VERSION ""

NS_ :

BS_:

BU_: VCU AUTO RMT
BO_ 1524 BcmMessage4: 8 VCU
 SG_ Ltemp : 8|8@1+ (1,-40) [-40|215] "℃"    AUTO,   RMT
 SG_ Ntemp : 16|8@1+ (1,-40) [-40|215] "℃"    AUTO,   RMT
 SG_ SafeBeltSta1 : 24|1@1+ (1,0) [0|1] ""    AUTO,   RMT
 SG_ SafeBeltSta2 : 25|1@1+ (1,0) [0|1] ""    AUTO,   RMT
 SG_ SafeBeltSta3 : 26|1@1+ (1,0) [0|1] ""    AUTO,   RMT
 SG_ SafeBeltSta4 : 27|1@1+ (1,0) [0|1] ""    AUTO,   RMT
 SG_ SafeBeltSta5 : 28|1@1+ (1,0) [0|1] ""    AUTO,   RMT
 SG_ SafeBeltSta6 : 29|1@1+ (1,0) [0|1] ""    AUTO,   RMT
 SG_ SeatSta1 : 30|1@1+ (1,0) [0|1] ""    AUTO,   RMT
 SG_ SeatSta2 : 31|1@1+ (1,0) [0|1] ""    AUTO,   RMT
 SG_ SeatSta3 : 32|1@1+ (1,0) [0|1] ""    AUTO,   RMT
 SG_ SeatSta4 : 33|1@1+ (1,0) [0|1] ""    AUTO,   RMT
 SG_ SeatSta5 : 34|1@1+ (1,0) [0|1] ""    AUTO,   RMT
 SG_ SeatSta6 : 35|1@1+ (1,0) [0|1] ""    AUTO,   RMT
 SG_ IoIn13 : 36|1@1+ (1,0) [0|1] ""    AUTO,   RMT
 SG_ IoIn14 : 37|1@1+ (1,0) [0|1] ""    AUTO,   RMT
 SG_ IoIn15 : 38|1@1+ (1,0) [0|1] ""    AUTO,   RMT
 SG_ IoIn16 : 39|1@1+ (1,0) [0|1] ""    AUTO,   RMT
 SG_ IoCur1 : 40|1@1+ (1,0) [0|1] ""    AUTO,   RMT
 SG_ IoCur2 : 41|1@1+ (1,0) [0|1] ""    AUTO,   RMT
 SG_ IoCur3 : 42|1@1+ (1,0) [0|1] ""    AUTO,   RMT
 SG_ IoCur4 : 43|1@1+ (1,0) [0|1] ""    AUTO,   RMT
 SG_ AdCVin : 44|1@1+ (1,0) [0|20] "mV"    AUTO,   RMT
 SG_ AdVVin5 : 46|10@1+ (10,0) [0|10000] "mV"    AUTO,   RMT

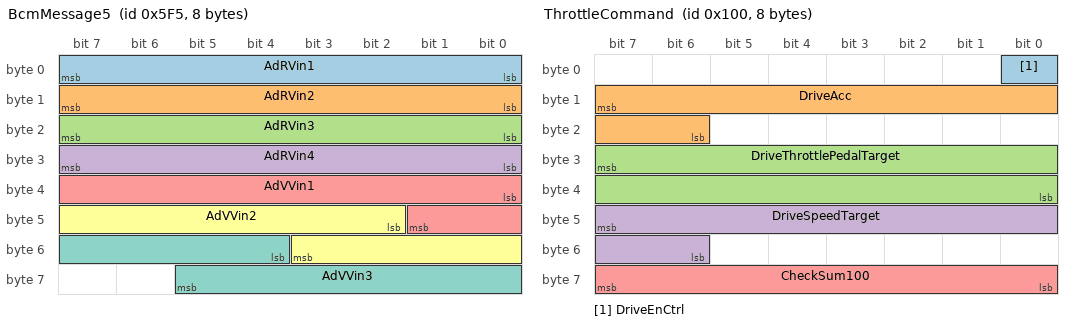
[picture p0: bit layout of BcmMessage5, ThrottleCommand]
BO_ 1525 BcmMessage5: 8 VCU
 SG_ AdRVin1 : 0|8@1+ (2,0) [0|500] "Ω"    AUTO,   RMT
 SG_ AdRVin2 : 8|8@1+ (2,0) [0|500] "Ω"    AUTO,   RMT
 SG_ AdRVin3 : 16|8@1+ (2,0) [0|500] "Ω"    AUTO,   RMT
 SG_ AdRVin4 : 24|8@1+ (2,0) [0|500] "Ω"    AUTO,   RMT
 SG_ AdVVin1 : 32|10@1+ (5,0) [0|3500] "mV"    AUTO,   RMT
 SG_ AdVVin2 : 42|10@1+ (5,0) [0|3500] "mV"    AUTO,   RMT
 SG_ AdVVin3 : 52|10@1+ (5,0) [0|3500] "mV"    AUTO,   RMT

BO_ 256 ThrottleCommand: 8 AUTO
 SG_ DriveEnCtrl : 0|1@0+ (1,0) [0|1] ""   VCU
 SG_ DriveAcc : 15|10@0+ (0.01,0) [0|10] "m/s^2"   VCU
 SG_ DriveThrottlePedalTarget : 31|16@0+ (0.1,0) [0|100] "%"   VCU
 SG_ DriveSpeedTarget : 47|10@0+ (0.01,0) [0|40.95] " m/s"   VCU
 SG_ CheckSum100 : 63|8@0+ (1,0) [0|255] ""   VCU

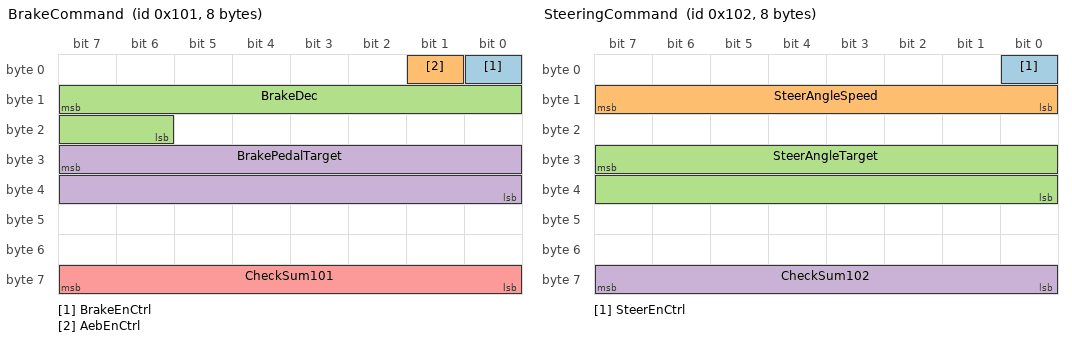
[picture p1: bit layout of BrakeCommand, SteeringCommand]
BO_ 257 BrakeCommand: 8 AUTO
 SG_ BrakeEnCtrl : 0|1@0+ (1,0) [0|1] ""   VCU
 SG_ AebEnCtrl : 1|1@0+ (1,0) [0|1] ""   VCU
 SG_ BrakeDec : 15|10@0+ (0.01,0) [0|10] "m/s^2"   VCU
 SG_ BrakePedalTarget : 31|16@0+ (0.1,0) [0|100] "%"   VCU
 SG_ CheckSum101 : 63|8@0+ (1,0) [0|255] ""   VCU

BO_ 258 SteeringCommand: 8 AUTO
 SG_ SteerEnCtrl : 0|1@0+ (1,0) [0|1] ""   VCU
 SG_ SteerAngleSpeed : 15|8@0+ (1,0) [0|250] "deg/s"   VCU
 SG_ SteerAngleTarget : 31|16@0+ (1,-500) [-465|465] "deg"   VCU
 SG_ CheckSum102 : 63|8@0+ (1,0) [0|255] ""   VCU

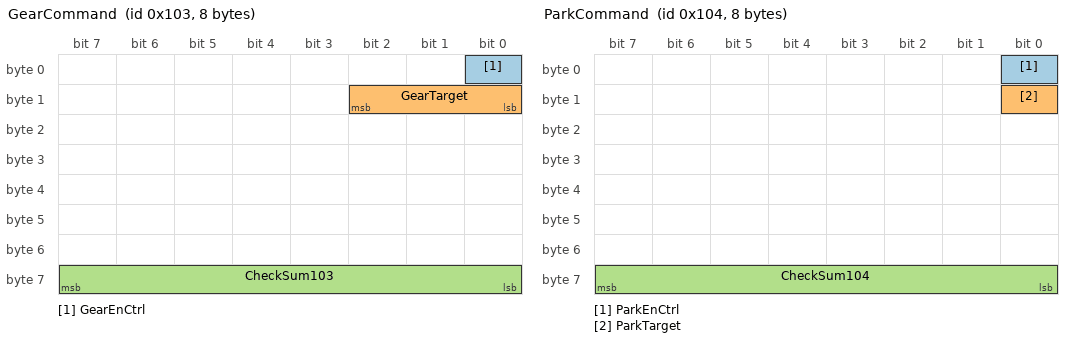
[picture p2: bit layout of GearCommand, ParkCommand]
BO_ 259 GearCommand: 8 AUTO
 SG_ GearEnCtrl : 0|1@0+ (1,0) [0|1] ""   VCU
 SG_ GearTarget : 10|3@0+ (1,0) [0|7] ""   VCU
 SG_ CheckSum103 : 63|8@0+ (1,0) [0|255] ""   VCU

BO_ 260 ParkCommand: 8 AUTO
 SG_ ParkEnCtrl : 0|1@0+ (1,0) [0|1] ""   VCU
 SG_ ParkTarget : 8|1@0+ (1,0) [0|1] ""   VCU
 SG_ CheckSum104 : 63|8@0+ (1,0) [0|255] ""   VCU

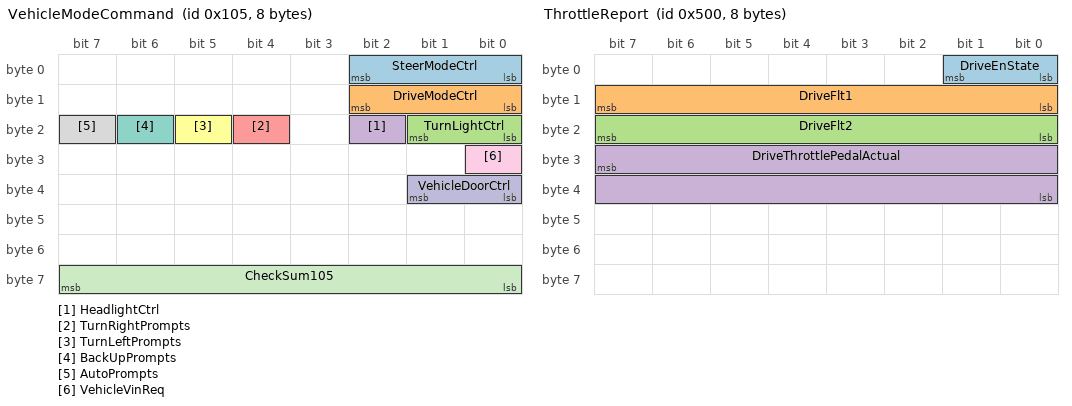
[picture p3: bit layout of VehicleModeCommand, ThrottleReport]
BO_ 261 VehicleModeCommand: 8 AUTO
 SG_ SteerModeCtrl : 2|3@0+ (1,0) [0|7] ""   VCU
 SG_ DriveModeCtrl : 10|3@0+ (1,0) [0|7] ""   VCU
 SG_ TurnLightCtrl : 17|2@0+ (1,0) [0|3] ""   VCU
 SG_ HeadlightCtrl : 18|1@0+ (1,0) [0|1] ""   VCU
 SG_ TurnRightPrompts : 20|1@0+ (1,0) [0|1] ""   VCU
 SG_ TurnLeftPrompts : 21|1@0+ (1,0) [0|1] ""   VCU
 SG_ BackUpPrompts : 22|1@0+ (1,0) [0|1] ""   VCU
 SG_ AutoPrompts : 23|1@0+ (1,0) [0|1] ""   VCU
 SG_ VehicleVinReq : 24|1@0+ (1,0) [0|1] ""   VCU
 SG_ VehicleDoorCtrl : 33|2@0+ (1,0) [0|3] ""   VCU
 SG_ CheckSum105 : 63|8@0+ (1,0) [0|255] ""   VCU

BO_ 1280 ThrottleReport: 8 VCU
 SG_ DriveEnState : 1|2@0+ (1,0) [0|3] ""    AUTO,   RMT
 SG_ DriveFlt1 : 15|8@0+ (1,0) [0|255] ""    AUTO,   RMT
 SG_ DriveFlt2 : 23|8@0+ (1,0) [0|255] ""    AUTO,   RMT
 SG_ DriveThrottlePedalActual : 31|16@0+ (0.1,0) [0|100] "%"    AUTO,   RMT

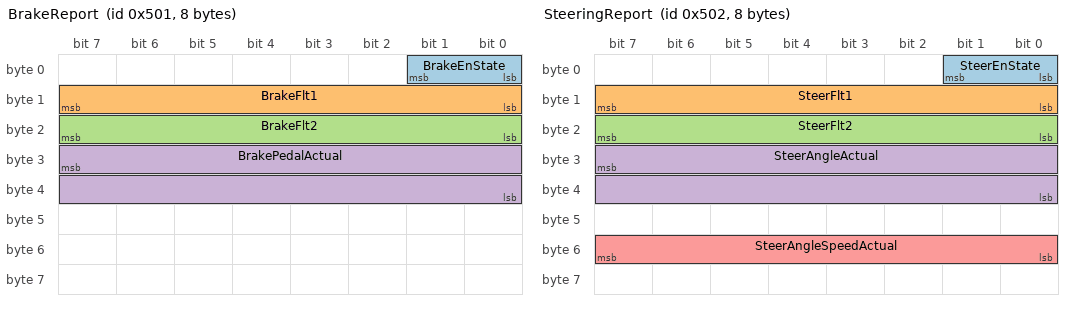
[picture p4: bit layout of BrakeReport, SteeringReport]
BO_ 1281 BrakeReport: 8 VCU
 SG_ BrakeEnState : 1|2@0+ (1,0) [0|3] ""    AUTO,   RMT
 SG_ BrakeFlt1 : 15|8@0+ (1,0) [0|255] ""    AUTO,   RMT
 SG_ BrakeFlt2 : 23|8@0+ (1,0) [0|255] ""    AUTO,   RMT
 SG_ BrakePedalActual : 31|16@0+ (0.1,0) [0|100] "%"    AUTO,   RMT

BO_ 1282 SteeringReport: 8 VCU
 SG_ SteerEnState : 1|2@0+ (1,0) [0|3] ""    AUTO,   RMT
 SG_ SteerFlt1 : 15|8@0+ (1,0) [0|255] ""    AUTO,   RMT
 SG_ SteerFlt2 : 23|8@0+ (1,0) [0|255] ""    AUTO,   RMT
 SG_ SteerAngleActual : 31|16@0+ (1,-500) [-465|465] "deg"    AUTO,   RMT
 SG_ SteerAngleSpeedActual : 55|8@0+ (1,0) [0|250] "deg/s"    AUTO,   RMT

BO_ 1283 GearReport: 8 VCU
 SG_ GearActual : 2|3@0+ (1,0) [0|7] ""    AUTO,   RMT
 SG_ GearFlt : 15|8@0+ (1,0) [0|255] ""    AUTO,   RMT

BO_ 1284 ParkReport: 8 VCU
 SG_ ParkingActual : 0|1@0+ (1,0) [0|1] ""    AUTO,   RMT
 SG_ ParkFlt : 15|8@0+ (1,0) [0|255] ""    AUTO,   RMT

BO_ 1285 VcuReport1: 8 VCU
 SG_ SteerModeStatus : 10|3@0+ (1,0) [0|7] ""    AUTO,   RMT
 SG_ BrakeLightActual : 11|1@0+ (1,0) [0|1] ""    AUTO,   RMT
 SG_ VehicleAcc : 7|12@0+ (0.01,0) [-10|10] "m/s^2"    AUTO,   RMT
 SG_ VehicleSpeed : 23|16@0- (0.001,0) [-32.768|32.767] "m/s"    AUTO,   RMT
 SG_ AebState : 32|1@0+ (1,0) [0|1] ""    AUTO,   RMT
 SG_ VehicleFrontCrashState : 33|1@0+ (1,0) [0|1] ""    AUTO,   RMT
 SG_ BackCrashState : 34|1@0+ (1,0) [0|1] ""    AUTO,   RMT
 SG_ VehicleModeState : 36|2@0+ (1,0) [0|3] ""    AUTO,   RMT
 SG_ DriveModeStatus : 39|3@0+ (1,0) [0|7] ""    AUTO,   RMT
 SG_ VehicleErrcode : 47|8@0+ (1,0) [0|255] ""    AUTO,   RMT
 SG_ CarWorkState : 51|4@0+ (1,0) [0|15] ""    AUTO,   RMT
 SG_ CarPowerState : 53|2@0+ (1,0) [0|3] ""    AUTO,   RMT
 SG_ AllowSelfDrivingRun : 54|1@0+ (1,0) [0|1] ""    AUTO,   RMT
 SG_ RcuConnectionStatus : 55|1@0+ (1,0) [0|1] ""    AUTO,   RMT
 SG_ TurnLightActual : 57|2@0+ (1,0) [0|3] ""    AUTO,   RMT
 SG_ HeadlightActual : 58|1@0+ (1,0) [0|1] ""    AUTO,   RMT
 SG_ ClearanceLampActural : 60|1@0+ (1,0) [0|1] ""    AUTO,   RMT
 SG_ VcuChassisEStopStaFb : 63|3@0+ (1,0) [0|7] ""    AUTO,   RMT

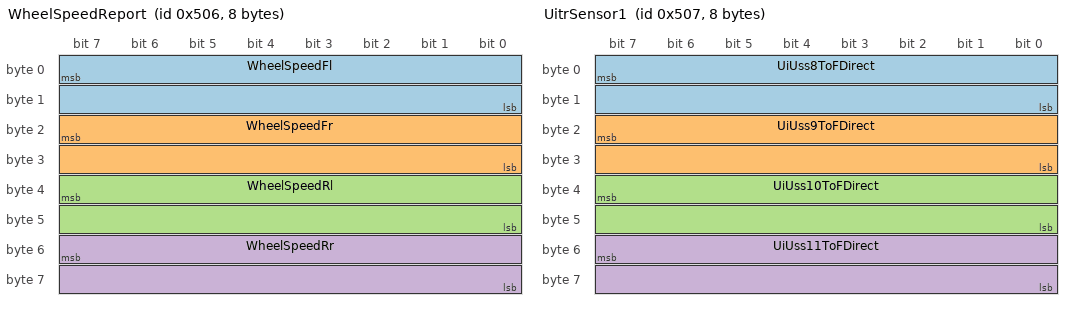
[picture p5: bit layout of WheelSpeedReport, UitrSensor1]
BO_ 1286 WheelSpeedReport: 8 VCU
 SG_ WheelSpeedFl : 7|16@0- (0.001,0) [0|65.535] "m/s"    AUTO,   RMT
 SG_ WheelSpeedFr : 23|16@0- (0.001,0) [0|65.535] "m/s"    AUTO,   RMT
 SG_ WheelSpeedRl : 39|16@0- (0.001,0) [0|65.535] "m/s"    AUTO,   RMT
 SG_ WheelSpeedRr : 55|16@0- (0.001,0) [0|65.535] "m/s"    AUTO,   RMT

BO_ 1287 UitrSensor1: 8 VCU
 SG_ UiUss8ToFDirect : 7|16@0+ (0.01724,0) [0|65535] "cm"    AUTO,   RMT
 SG_ UiUss9ToFDirect : 23|16@0+ (0.01724,0) [0|65535] "cm"    AUTO,   RMT
 SG_ UiUss10ToFDirect : 39|16@0+ (0.01724,0) [0|65535] "cm"    AUTO,   RMT
 SG_ UiUss11ToFDirect : 55|16@0+ (0.01724,0) [0|65535] "cm"    AUTO,   RMT

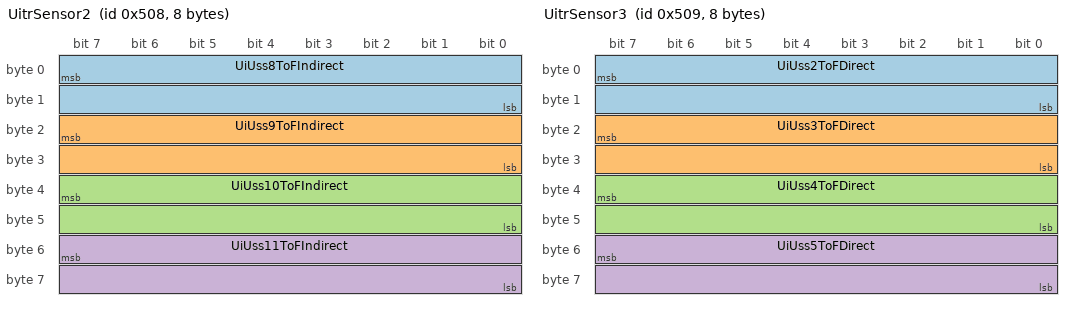
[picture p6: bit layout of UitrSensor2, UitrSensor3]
BO_ 1288 UitrSensor2: 8 VCU
 SG_ UiUss8ToFIndirect : 7|16@0+ (0.01724,0) [0|65535] "cm"    AUTO,   RMT
 SG_ UiUss9ToFIndirect : 23|16@0+ (0.01724,0) [0|65535] "cm"    AUTO,   RMT
 SG_ UiUss10ToFIndirect : 39|16@0+ (0.01724,0) [0|65535] "cm"    AUTO,   RMT
 SG_ UiUss11ToFIndirect : 55|16@0+ (0.01724,0) [0|65535] "cm"    AUTO,   RMT

BO_ 1289 UitrSensor3: 8 VCU
 SG_ UiUss2ToFDirect : 7|16@0+ (0.01724,0) [0|65535] "cm"    AUTO,   RMT
 SG_ UiUss3ToFDirect : 23|16@0+ (0.01724,0) [0|65535] "cm"    AUTO,   RMT
 SG_ UiUss4ToFDirect : 39|16@0+ (0.01724,0) [0|65535] "cm"    AUTO,   RMT
 SG_ UiUss5ToFDirect : 55|16@0+ (0.01724,0) [0|65535] "cm"    AUTO,   RMT

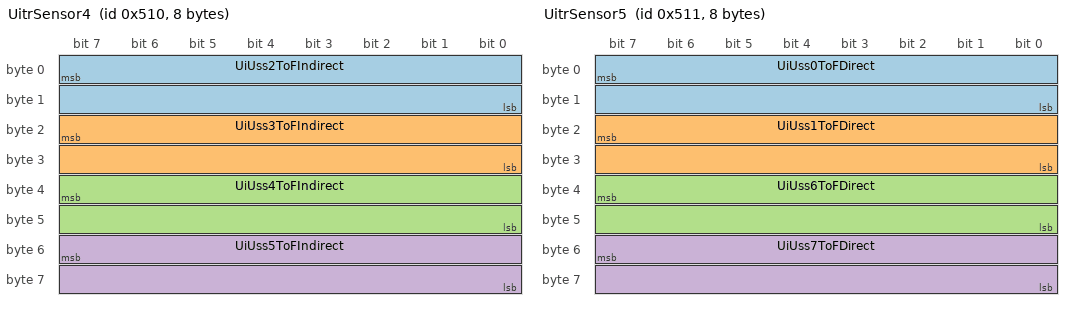
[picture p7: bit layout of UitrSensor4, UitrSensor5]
BO_ 1296 UitrSensor4: 8 VCU
 SG_ UiUss2ToFIndirect : 7|16@0+ (0.01724,0) [0|65535] "cm"    AUTO,   RMT
 SG_ UiUss3ToFIndirect : 23|16@0+ (0.01724,0) [0|65535] "cm"    AUTO,   RMT
 SG_ UiUss4ToFIndirect : 39|16@0+ (0.01724,0) [0|65535] "cm"    AUTO,   RMT
 SG_ UiUss5ToFIndirect : 55|16@0+ (0.01724,0) [0|65535] "cm"    AUTO,   RMT

BO_ 1297 UitrSensor5: 8 VCU
 SG_ UiUss0ToFDirect : 7|16@0+ (0.01724,0) [0|65535] "cm"    AUTO,   RMT
 SG_ UiUss1ToFDirect : 23|16@0+ (0.01724,0) [0|65535] "cm"    AUTO,   RMT
 SG_ UiUss6ToFDirect : 39|16@0+ (0.01724,0) [0|65535] "cm"    AUTO,   RMT
 SG_ UiUss7ToFDirect : 55|16@0+ (0.01724,0) [0|65535] "cm"    AUTO,   RMT

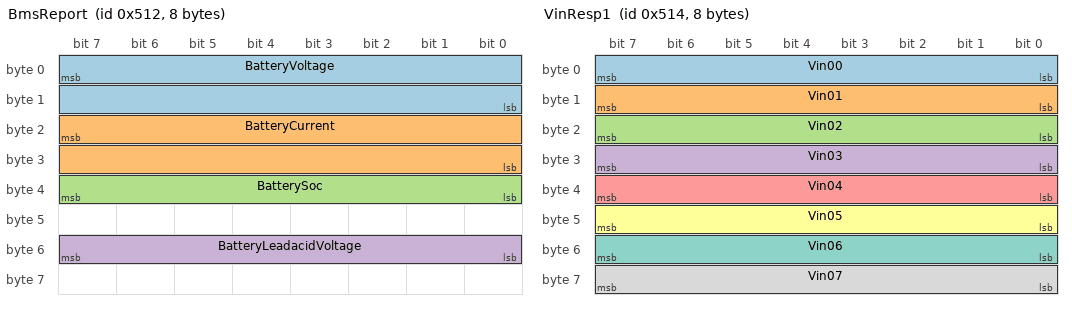
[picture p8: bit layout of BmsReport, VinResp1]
BO_ 1298 BmsReport: 8 VCU
 SG_ BatteryVoltage : 7|16@0+ (0.01,0) [0|300] "V"    AUTO,   RMT
 SG_ BatteryCurrent : 23|16@0- (0.1,-3200) [-3200|3353.5] "A"    AUTO,   RMT
 SG_ BatterySoc : 39|8@0+ (1,0) [0|100] "%"    AUTO,   RMT
 SG_ BatteryLeadacidVoltage : 55|8@0+ (1,0) [0|255] "V"    AUTO,   RMT

BO_ 1300 VinResp1: 8 VCU
 SG_ Vin00 : 7|8@0+ (1,0) [0|255] ""    AUTO,   RMT
 SG_ Vin01 : 15|8@0+ (1,0) [0|255] ""    AUTO,   RMT
 SG_ Vin02 : 23|8@0+ (1,0) [0|255] ""    AUTO,   RMT
 SG_ Vin03 : 31|8@0+ (1,0) [0|255] ""    AUTO,   RMT
 SG_ Vin04 : 39|8@0+ (1,0) [0|255] ""    AUTO,   RMT
 SG_ Vin05 : 47|8@0+ (1,0) [0|255] ""    AUTO,   RMT
 SG_ Vin06 : 55|8@0+ (1,0) [0|255] ""    AUTO,   RMT
 SG_ Vin07 : 63|8@0+ (1,0) [0|255] ""    AUTO,   RMT

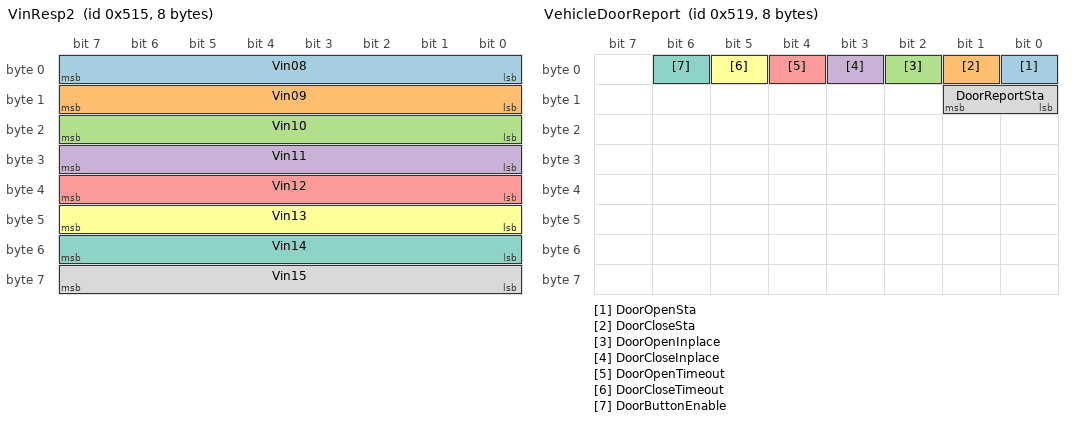
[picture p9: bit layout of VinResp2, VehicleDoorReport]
BO_ 1301 VinResp2: 8 VCU
 SG_ Vin08 : 7|8@0+ (1,0) [0|255] ""    AUTO,   RMT
 SG_ Vin09 : 15|8@0+ (1,0) [0|255] ""    AUTO,   RMT
 SG_ Vin10 : 23|8@0+ (1,0) [0|255] ""    AUTO,   RMT
 SG_ Vin11 : 31|8@0+ (1,0) [0|255] ""    AUTO,   RMT
 SG_ Vin12 : 39|8@0+ (1,0) [0|255] ""    AUTO,   RMT
 SG_ Vin13 : 47|8@0+ (1,0) [0|255] ""    AUTO,   RMT
 SG_ Vin14 : 55|8@0+ (1,0) [0|255] ""    AUTO,   RMT
 SG_ Vin15 : 63|8@0+ (1,0) [0|255] ""    AUTO,   RMT

BO_ 1302 VinResp3: 8 VCU
 SG_ Vin16 : 7|8@0+ (1,0) [0|255] ""    AUTO,   RMT

BO_ 1305 VehicleDoorReport: 8 VCU
 SG_ DoorOpenSta : 0|1@0+ (1,0) [0|1] ""    AUTO,   RMT
 SG_ DoorCloseSta : 1|1@0+ (1,0) [0|1] "" Vector__XXX
 SG_ DoorOpenInplace : 2|1@0+ (1,0) [0|1] "" Vector__XXX
 SG_ DoorCloseInplace : 3|1@0+ (1,0) [0|1] "" Vector__XXX
 SG_ DoorOpenTimeout : 4|1@0+ (1,0) [0|1] "" Vector__XXX
 SG_ DoorCloseTimeout : 5|1@0+ (1,0) [0|1] "" Vector__XXX
 SG_ DoorButtonEnable : 6|1@0+ (1,0) [0|1] "" Vector__XXX
 SG_ DoorReportSta : 9|2@0+ (1,0) [0|3] "" Vector__XXX

BO_ 928 AutoMessage: 8 AUTO
 SG_ AutoDriveMode : 7|8@0+ (1,0) [0|255] ""   VCU,  RMT
 SG_ AutoHeartbeat : 63|8@0+ (1,0) [0|255] ""   VCU,  RMT

BO_ 944 RemoteMessage: 8 RMT
 SG_ RemoteDriveMode : 7|8@0+ (1,0) [0|255] ""    VCU ,   AUTO
 SG_ RemoteHeartbeat : 63|8@0+ (1,0) [0|255] ""    VCU ,   AUTO

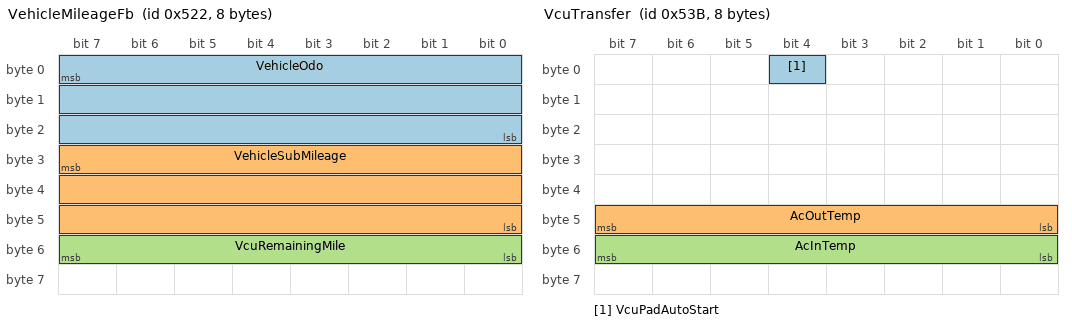
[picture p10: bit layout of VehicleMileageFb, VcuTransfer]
BO_ 1314 VehicleMileageFb: 8 VCU
 SG_ VehicleOdo : 7|24@0+ (0.1,0) [0|1677721.5] "km"    AUTO,   RMT
 SG_ VehicleSubMileage : 31|24@0+ (0.001,0) [0|167772.215] "km"    AUTO,   RMT
 SG_ VcuRemainingMile : 55|8@0+ (1,0) [0|255] "km"    AUTO,   RMT

BO_ 1339 VcuTransfer: 8 VCU
 SG_ VcuPadAutoStart : 4|1@0+ (1,0) [0|1] ""    AUTO,   RMT
 SG_ AcOutTemp : 47|8@0- (1,0) [-128|127] "℃"    AUTO,   RMT
 SG_ AcInTemp : 55|8@0- (1,0) [-128|127] "℃"    AUTO,   RMT

CM_ SG_ 1524 Ltemp "交流充L线温度";
CM_ SG_ 1524 Ntemp "交流充N线温度";
CM_ SG_ 1524 SafeBeltSta1 "前左安全带状态";
CM_ SG_ 1524 SafeBeltSta2 "前中安全带状态";
CM_ SG_ 1524 SafeBeltSta3 "前右安全带状态";
CM_ SG_ 1524 SafeBeltSta4 "后左安全带状态";
CM_ SG_ 1524 SafeBeltSta5 "后中安全带状态";
CM_ SG_ 1524 SafeBeltSta6 "后右安全带状态";
CM_ SG_ 1524 SeatSta1 "前左座椅状态";
CM_ SG_ 1524 SeatSta2 "前中座椅状态";
CM_ SG_ 1524 SeatSta3 "前右座椅状态";
CM_ SG_ 1524 SeatSta4 "后左座椅状态";
CM_ SG_ 1524 SeatSta5 "后中座椅状态";
CM_ SG_ 1524 SeatSta6 "后右座椅状态";
CM_ SG_ 1524 IoIn13 "开关量输入口13";
CM_ SG_ 1524 IoIn14 "开关量输入口14";
CM_ SG_ 1524 IoIn15 "开关量输入口15";
CM_ SG_ 1524 IoIn16 "开关量输入口16";
CM_ SG_ 1524 IoCur1 "电流型输入口1";
CM_ SG_ 1524 IoCur2 "电流型输入口2";
CM_ SG_ 1524 IoCur3 "电流型输入口3";
CM_ SG_ 1524 IoCur4 "电流型输入口4";
CM_ SG_ 1524 AdCVin "电流型传感器输入口";
CM_ SG_ 1524 AdVVin5 "电压型传感器输入口4(0~10V)";
CM_ SG_ 1525 AdRVin1 "电阻型传感器输入口1";
CM_ SG_ 1525 AdRVin2 "电阻型传感器输入口2";
CM_ SG_ 1525 AdRVin3 "电阻型传感器输入口3";
CM_ SG_ 1525 AdRVin4 "电阻型传感器输入口4";
CM_ SG_ 1525 AdVVin1 "电压型传感器输入口1(烟雾传感器）";
CM_ SG_ 1525 AdVVin2 "电压型传感器输入口2（CO2传感器）";
CM_ SG_ 1525 AdVVin3 "电压型传感器输入口3";
CM_ SG_ 256 DriveEnCtrl "加速使能";
CM_ SG_ 256 DriveAcc "车辆目标纵向加速度（可选）";
CM_ SG_ 256 DriveThrottlePedalTarget "虚拟目标加速踏板位置";
CM_ SG_ 256 DriveSpeedTarget "驾驶速度";
CM_ SG_ 256 CheckSum100 "循环计数";
CM_ SG_ 257 BrakeEnCtrl "制动使能";
CM_ SG_ 257 AebEnCtrl "AEB使能";
CM_ SG_ 257 BrakeDec "目标减速度（可选）";
CM_ SG_ 257 BrakePedalTarget "虚拟目标制动踏板位置";
CM_ SG_ 257 CheckSum101 "循环计数";
CM_ SG_ 258 SteerEnCtrl "转向使能";
CM_ SG_ 258 SteerAngleSpeed "目标前轮转速 （方向盘转速）";
CM_ SG_ 258 SteerAngleTarget "目标前轮转向角（方向盘转角）";
CM_ SG_ 258 CheckSum102 "循环计数";
CM_ SG_ 259 GearEnCtrl "档位控制使能";
CM_ SG_ 259 GearTarget "目标档位";
CM_ SG_ 259 CheckSum103 "循环计数";
CM_ SG_ 260 ParkEnCtrl "驻车使能";
CM_ SG_ 260 ParkTarget "驻车指令";
CM_ SG_ 260 CheckSum104 "循环计数";
CM_ SG_ 261 SteerModeCtrl "转向模式控制";
CM_ SG_ 261 DriveModeCtrl "驾驶模式控制";
CM_ SG_ 261 TurnLightCtrl "转向灯控制";
CM_ SG_ 261 HeadlightCtrl "近光灯控制";
CM_ SG_ 261 TurnRightPrompts "右转语音提示";
CM_ SG_ 261 TurnLeftPrompts "左转语音提示";
CM_ SG_ 261 BackUpPrompts "倒挡语音提示";
CM_ SG_ 261 AutoPrompts "自动驾驶警告语音提示";
CM_ SG_ 261 VehicleVinReq "VIN请求（车架号） （预留）";
CM_ SG_ 261 VehicleDoorCtrl "门控制";
CM_ SG_ 261 CheckSum105 "循环计数";
CM_ SG_ 1280 DriveEnState "驱动状态";
CM_ SG_ 1280 DriveFlt1 "驱动故障信息1";
CM_ SG_ 1280 DriveFlt2 "驱动故障信息2（控制指令周期故障）";
CM_ SG_ 1280 DriveThrottlePedalActual "加速踏板位置反馈";
CM_ SG_ 1281 BrakeEnState "制动状态";
CM_ SG_ 1281 BrakeFlt1 "制动故障信息1";
CM_ SG_ 1281 BrakeFlt2 "制动故障信息2";
CM_ SG_ 1281 BrakePedalActual "制动踏板位置反馈";
CM_ SG_ 1282 SteerEnState "转向状态";
CM_ SG_ 1282 SteerFlt1 "转向故障信息1";
CM_ SG_ 1282 SteerFlt2 "转向故障信息2";
CM_ SG_ 1282 SteerAngleActual "转向角度反馈";
CM_ SG_ 1282 SteerAngleSpeedActual "转速反馈";
CM_ SG_ 1283 GearActual "档位防亏";
CM_ SG_ 1283 GearFlt "档位故障信息";
CM_ SG_ 1284 ParkingActual "驻车反馈";
CM_ SG_ 1284 ParkFlt "驻车故障信息";
CM_ SG_ 1285 SteerModeStatus "当前转向状态";
CM_ SG_ 1285 BrakeLightActual "当前刹车灯状态";
CM_ SG_ 1285 VehicleAcc "纵向加（减）速度（可选）";
CM_ SG_ 1285 VehicleSpeed "车速";
CM_ SG_ 1285 AebState "AEB状态";
CM_ SG_ 1285 VehicleErrcode "故障码";
CM_ SG_ 1285 CarWorkState "车辆工作状态";
CM_ SG_ 1285 CarPowerState "车辆电源状态";
CM_ SG_ 1285 AllowSelfDrivingRun "允许自动驾驶行驶指令";
CM_ SG_ 1285 RcuConnectionStatus "遥控器连接状态";
CM_ SG_ 1285 TurnLightActual "转向灯状态";
CM_ SG_ 1285 HeadlightActual "灯状态";
CM_ SG_ 1285 ClearanceLampActural "示宽灯状态";
CM_ SG_ 1285 VcuChassisEStopStaFb "急停状态反馈";
CM_ SG_ 1298 BatteryVoltage "电池电压";
CM_ SG_ 1298 BatteryCurrent "电池电流";
CM_ SG_ 1298 BatterySoc "电池SOC";
CM_ SG_ 1305 DoorOpenSta "开门中";
CM_ SG_ 1305 DoorCloseSta "关门中";
CM_ SG_ 1305 DoorOpenInplace "开门到位";
CM_ SG_ 1305 DoorCloseInplace "关门到位";
CM_ SG_ 1305 DoorOpenTimeout "开门故障";
CM_ SG_ 1305 DoorCloseTimeout "关门故障";
CM_ SG_ 1305 DoorButtonEnable "门按钮使能状态";
CM_ SG_ 928 AutoDriveMode "自驾状态";
CM_ SG_ 928 AutoHeartbeat "自动驾驶心跳包";
CM_ SG_ 944 RemoteDriveMode "远控状态";
CM_ SG_ 944 RemoteHeartbeat "远控心跳包";
CM_ SG_ 1314 VehicleOdo "总计里程";
CM_ SG_ 1314 VehicleSubMileage "小计里程";
CM_ SG_ 1314 VcuRemainingMile "剩余里程";
CM_ SG_ 1339 VcuPadAutoStart "PAD自动驾驶启动按钮";
CM_ SG_ 1339 AcOutTemp "车外温度";
CM_ SG_ 1339 AcInTemp "车内温度";

BA_DEF_ BO_ "GenMsgCycleTime" INT 0 65535;
BA_DEF_ BO_  "GenMsgSendType" ENUM  "Cyclic","Event","IfActive","CE","CA","NoMsgSendType";
BA_DEF_DEF_ "GenMsgCycleTime" 1000;
BA_DEF_DEF_  "GenMsgSendType" "Cyclic";
BA_ "GenMsgCycleTime" BO_ 1524 500;
BA_ "GenMsgCycleTime" BO_ 1525 500;
BA_ "GenMsgCycleTime" BO_ 256 20;
BA_ "GenMsgCycleTime" BO_ 257 20;
BA_ "GenMsgCycleTime" BO_ 258 20;
BA_ "GenMsgCycleTime" BO_ 259 50;
BA_ "GenMsgCycleTime" BO_ 260 20;
BA_ "GenMsgCycleTime" BO_ 261 20;
BA_ "GenMsgCycleTime" BO_ 1280 20;
BA_ "GenMsgCycleTime" BO_ 1281 20;
BA_ "GenMsgCycleTime" BO_ 1282 20;
BA_ "GenMsgCycleTime" BO_ 1283 50;
BA_ "GenMsgCycleTime" BO_ 1284 50;
BA_ "GenMsgCycleTime" BO_ 1285 20;
BA_ "GenMsgCycleTime" BO_ 1286 20;
BA_ "GenMsgCycleTime" BO_ 1287 200;
BA_ "GenMsgCycleTime" BO_ 1288 200;
BA_ "GenMsgCycleTime" BO_ 1289 200;
BA_ "GenMsgCycleTime" BO_ 1296 200;
BA_ "GenMsgCycleTime" BO_ 1297 200;
BA_ "GenMsgCycleTime" BO_ 1298 20;
BA_ "GenMsgCycleTime" BO_ 1300 500;
BA_ "GenMsgCycleTime" BO_ 1301 500;
BA_ "GenMsgCycleTime" BO_ 1302 500;
BA_ "GenMsgCycleTime" BO_ 1305 100;
BA_ "GenMsgCycleTime" BO_ 928 100;
BA_ "GenMsgCycleTime" BO_ 944 100;
BA_ "GenMsgCycleTime" BO_ 1314 100;
BA_ "GenMsgCycleTime" BO_ 1339 100;
